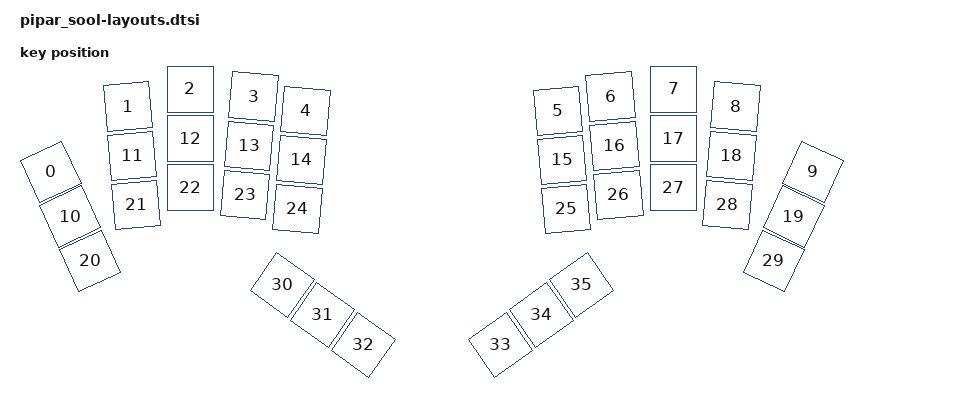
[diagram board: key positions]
#include <physical_layouts.dtsi>

/ {
    physical_layout0: physical_layout_0 {
        compatible = "zmk,physical-layout";
        display-name = "pipar_sool-layout";
        transform = <&matrix_transform0>;

        keys  //                     w   h    x    y     rot    rx    ry
            = <&key_physical_attrs 100 100    0  166 (-2500)    50   216>
            , <&key_physical_attrs 100 100  155   35  (-500)   205    85>
            , <&key_physical_attrs 100 100  279    0       0     0     0>
            , <&key_physical_attrs 100 100  406   15     500   456    65>
            , <&key_physical_attrs 100 100  510   44     500   560    94>
            , <&key_physical_attrs 100 100 1015   44  (-500)  1065    94>
            , <&key_physical_attrs 100 100 1120   15  (-500)  1170    65>
            , <&key_physical_attrs 100 100 1246    0       0     0     0>
            , <&key_physical_attrs 100 100 1370   35     500  1420    85>
            , <&key_physical_attrs 100 100 1525  166    2500  1575   216>
            , <&key_physical_attrs 100 100   39  255 (-2500)    89   305>
            , <&key_physical_attrs 100 100  163  134  (-500)   213   184>
            , <&key_physical_attrs 100 100  279   99       0     0     0>
            , <&key_physical_attrs 100 100  397  114     500   447   164>
            , <&key_physical_attrs 100 100  502  142     500   552   192>
            , <&key_physical_attrs 100 100 1023  142  (-500)  1073   192>
            , <&key_physical_attrs 100 100 1128  114  (-500)  1178   164>
            , <&key_physical_attrs 100 100 1246   99       0     0     0>
            , <&key_physical_attrs 100 100 1362  134     500  1412   184>
            , <&key_physical_attrs 100 100 1486  255    2500  1536   305>
            , <&key_physical_attrs 100 100   79  344 (-2500)   129   394>
            , <&key_physical_attrs 100 100  171  232  (-500)   221   282>
            , <&key_physical_attrs 100 100  279  197       0     0     0>
            , <&key_physical_attrs 100 100  389  212     500   439   262>
            , <&key_physical_attrs 100 100  494  240     500   544   290>
            , <&key_physical_attrs 100 100 1031  240  (-500)  1081   290>
            , <&key_physical_attrs 100 100 1136  212  (-500)  1186   262>
            , <&key_physical_attrs 100 100 1246  197       0     0     0>
            , <&key_physical_attrs 100 100 1354  232     500  1404   282>
            , <&key_physical_attrs 100 100 1446  344    2500  1496   394>
            , <&key_physical_attrs 100 100  463  392    3500   513   442>
            , <&key_physical_attrs 100 100  544  452    3500   594   502>
            , <&key_physical_attrs 100 100  625  512    3500   675   562>
            , <&key_physical_attrs 100 100  900  512 (-3500)   950   562>
            , <&key_physical_attrs 100 100  981  452 (-3500)  1031   502>
            , <&key_physical_attrs 100 100 1062  392 (-3500)  1112   442>
            ;
    };
};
